# QSPI1 register map
Registers from a debugger description file.
Registers are 32-bit, access not given, no defined reset value unless marked. A register's access mark holds for its fields unless they carry their own. Addresses are absolute; registers are grouped by the start of their names; lines under a group give offsets from that group; [hi:lo] are bit positions; {n}, {i} and the like mark numbered series; 'fields as' and 'values as' point back to an identical list; <NAME> marks a mode.

## QSPI1
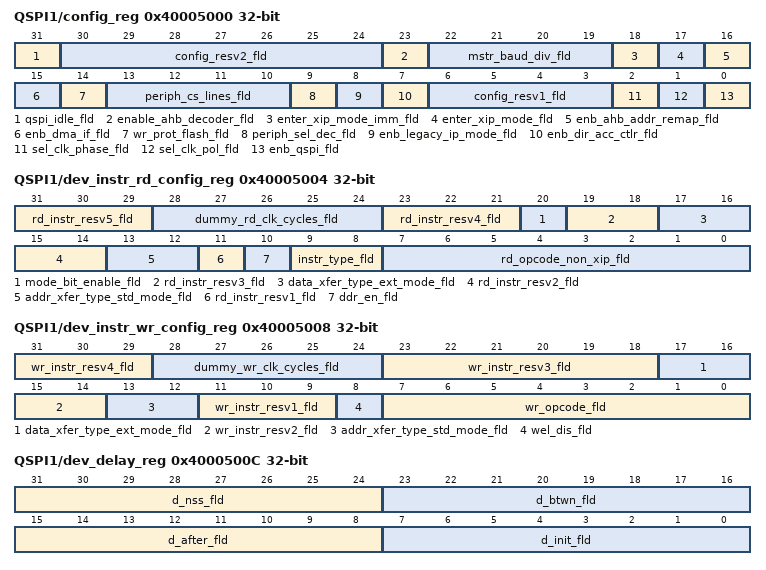
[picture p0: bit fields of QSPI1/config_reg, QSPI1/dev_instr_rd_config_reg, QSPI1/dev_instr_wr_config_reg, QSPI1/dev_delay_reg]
0x40005000 QSPI1/config_reg
  [31] qspi_idle_fld, [30:24] config_resv2_fld, [23] enable_ahb_decoder_fld, [22:19] mstr_baud_div_fld, [18] enter_xip_mode_imm_fld, [17] enter_xip_mode_fld, [16] enb_ahb_addr_remap_fld, [15] enb_dma_if_fld, [14] wr_prot_flash_fld, [13:10] periph_cs_lines_fld, [9] periph_sel_dec_fld, [8] enb_legacy_ip_mode_fld, [7] enb_dir_acc_ctlr_fld, [6:3] config_resv1_fld, [2] sel_clk_phase_fld, [1] sel_clk_pol_fld, [0] enb_qspi_fld
0x40005004 QSPI1/dev_instr_rd_config_reg
  [31:29] rd_instr_resv5_fld, [28:24] dummy_rd_clk_cycles_fld, [23:21] rd_instr_resv4_fld, [20] mode_bit_enable_fld, [19:18] rd_instr_resv3_fld, [17:16] data_xfer_type_ext_mode_fld, [15:14] rd_instr_resv2_fld, [13:12] addr_xfer_type_std_mode_fld, [11] rd_instr_resv1_fld, [10] ddr_en_fld, [9:8] instr_type_fld, [7:0] rd_opcode_non_xip_fld
0x40005008 QSPI1/dev_instr_wr_config_reg
  [31:29] wr_instr_resv4_fld, [28:24] dummy_wr_clk_cycles_fld, [23:18] wr_instr_resv3_fld, [17:16] data_xfer_type_ext_mode_fld, [15:14] wr_instr_resv2_fld, [13:12] addr_xfer_type_std_mode_fld, [11:9] wr_instr_resv1_fld, [8] wel_dis_fld, [7:0] wr_opcode_fld
0x4000500C QSPI1/dev_delay_reg
  [31:24] d_nss_fld, [23:16] d_btwn_fld, [15:8] d_after_fld, [7:0] d_init_fld
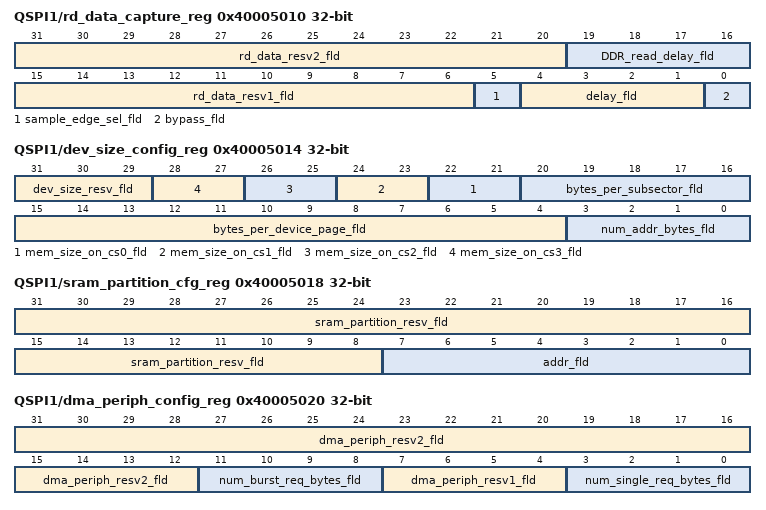
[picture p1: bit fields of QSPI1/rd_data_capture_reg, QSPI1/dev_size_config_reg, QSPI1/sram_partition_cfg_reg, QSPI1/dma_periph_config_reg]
0x40005010 QSPI1/rd_data_capture_reg
  [31:20] rd_data_resv2_fld, [19:16] DDR_read_delay_fld, [15:6] rd_data_resv1_fld, [5] sample_edge_sel_fld, [4:1] delay_fld, [0] bypass_fld
0x40005014 QSPI1/dev_size_config_reg
  [31:29] dev_size_resv_fld, [2n+22:2n+21] mem_size_on_cs{n}_fld (n=0..3), [20:16] bytes_per_subsector_fld, [15:4] bytes_per_device_page_fld, [3:0] num_addr_bytes_fld
0x40005018 QSPI1/sram_partition_cfg_reg
  [31:8] sram_partition_resv_fld, [7:0] addr_fld
0x4000501C QSPI1/ind_AHB_addr_trigger_reg
  [31:0] addr_fld
0x40005020 QSPI1/dma_periph_config_reg
  [31:12] dma_periph_resv2_fld, [11:8] num_burst_req_bytes_fld, [7:4] dma_periph_resv1_fld, [3:0] num_single_req_bytes_fld
0x40005024 QSPI1/remap_addr_reg
  [31:0] value_fld
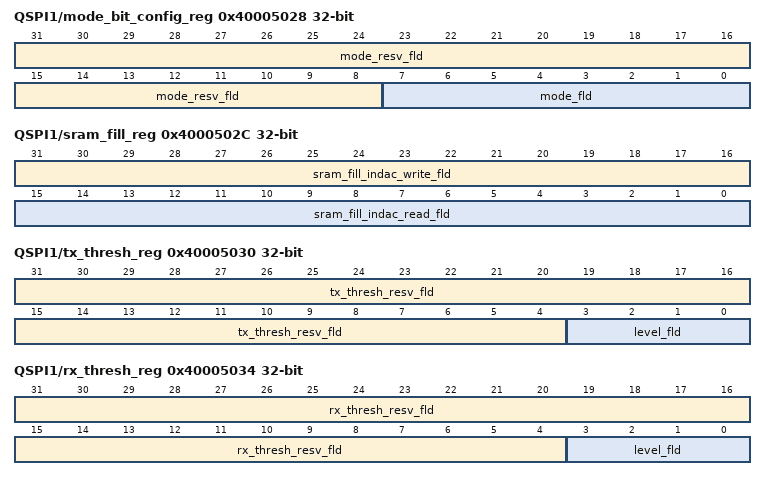
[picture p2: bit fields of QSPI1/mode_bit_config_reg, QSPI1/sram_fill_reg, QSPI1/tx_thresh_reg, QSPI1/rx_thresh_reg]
0x40005028 QSPI1/mode_bit_config_reg
  [31:8] mode_resv_fld, [7:0] mode_fld
0x4000502C QSPI1/sram_fill_reg
  [31:16] sram_fill_indac_write_fld, [15:0] sram_fill_indac_read_fld
0x40005030 QSPI1/tx_thresh_reg
  [31:4] tx_thresh_resv_fld, [3:0] level_fld
0x40005034 QSPI1/rx_thresh_reg
  [31:4] rx_thresh_resv_fld, [3:0] level_fld
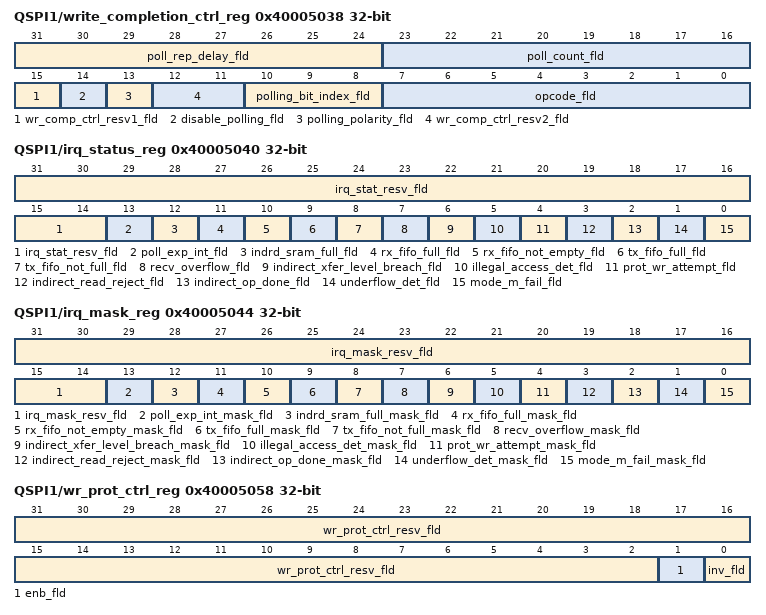
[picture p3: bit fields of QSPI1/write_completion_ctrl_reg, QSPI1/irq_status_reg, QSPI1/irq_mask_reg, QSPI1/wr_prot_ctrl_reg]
0x40005038 QSPI1/write_completion_ctrl_reg
  [31:24] poll_rep_delay_fld, [23:16] poll_count_fld, [15] wr_comp_ctrl_resv1_fld, [14] disable_polling_fld, [13] polling_polarity_fld, [12:11] wr_comp_ctrl_resv2_fld, [10:8] polling_bit_index_fld, [7:0] opcode_fld
0x4000503C QSPI1/no_of_polls_bef_exp_reg
  [31:0] no_of_polls_bef_exp_fld
0x40005040 QSPI1/irq_status_reg
  [31:14] irq_stat_resv_fld, [13] poll_exp_int_fld, [12] indrd_sram_full_fld, [11] rx_fifo_full_fld, [10] rx_fifo_not_empty_fld, [9] tx_fifo_full_fld, [8] tx_fifo_not_full_fld, [7] recv_overflow_fld, [6] indirect_xfer_level_breach_fld, [5] illegal_access_det_fld, [4] prot_wr_attempt_fld, [3] indirect_read_reject_fld, [2] indirect_op_done_fld, [1] underflow_det_fld, [0] mode_m_fail_fld
0x40005044 QSPI1/irq_mask_reg
  [31:14] irq_mask_resv_fld, [13] poll_exp_int_mask_fld, [12] indrd_sram_full_mask_fld, [11] rx_fifo_full_mask_fld, [10] rx_fifo_not_empty_mask_fld, [9] tx_fifo_full_mask_fld, [8] tx_fifo_not_full_mask_fld, [7] recv_overflow_mask_fld, [6] indirect_xfer_level_breach_mask_fld, [5] illegal_access_det_mask_fld, [4] prot_wr_attempt_mask_fld, [3] indirect_read_reject_mask_fld, [2] indirect_op_done_mask_fld, [1] underflow_det_mask_fld, [0] mode_m_fail_mask_fld
0x40005050 QSPI1/lower_wr_prot_reg
  [31:0] subsector_fld
0x40005054 QSPI1/upper_wr_prot_reg
  [31:0] subsector_fld
0x40005058 QSPI1/wr_prot_ctrl_reg
  [31:2] wr_prot_ctrl_resv_fld, [1] enb_fld, [0] inv_fld
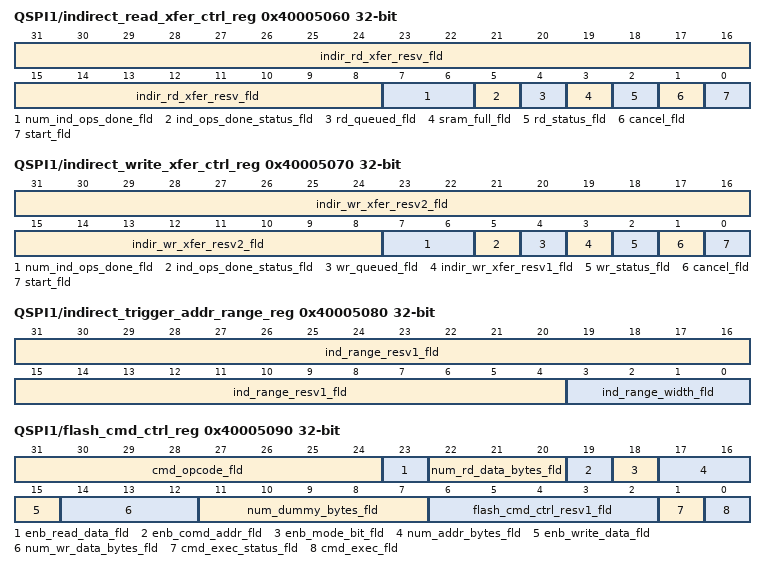
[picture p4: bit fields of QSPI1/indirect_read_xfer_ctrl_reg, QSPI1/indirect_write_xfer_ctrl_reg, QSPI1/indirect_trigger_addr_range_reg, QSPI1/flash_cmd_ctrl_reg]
0x40005060 QSPI1/indirect_read_xfer_ctrl_reg
  [31:8] indir_rd_xfer_resv_fld, [7:6] num_ind_ops_done_fld, [5] ind_ops_done_status_fld, [4] rd_queued_fld, [3] sram_full_fld, [2] rd_status_fld, [1] cancel_fld, [0] start_fld
0x40005064 QSPI1/indirect_read_xfer_watermark_reg
  [31:0] level_fld
0x40005068 QSPI1/indirect_read_xfer_start_reg
  [31:0] addr_fld
0x4000506C QSPI1/indirect_read_xfer_num_bytes_reg
  [31:0] value_fld
0x40005070 QSPI1/indirect_write_xfer_ctrl_reg
  [31:8] indir_wr_xfer_resv2_fld, [7:6] num_ind_ops_done_fld, [5] ind_ops_done_status_fld, [4] wr_queued_fld, [3] indir_wr_xfer_resv1_fld, [2] wr_status_fld, [1] cancel_fld, [0] start_fld
0x40005074 QSPI1/indirect_write_xfer_watermark_reg
  [31:0] level_fld
0x40005078 QSPI1/indirect_write_xfer_start_reg
  [31:0] addr_fld
0x4000507C QSPI1/indirect_write_xfer_num_bytes_reg
  [31:0] value_fld
0x40005080 QSPI1/indirect_trigger_addr_range_reg
  [31:4] ind_range_resv1_fld, [3:0] ind_range_width_fld
0x40005090 QSPI1/flash_cmd_ctrl_reg
  [31:24] cmd_opcode_fld, [23] enb_read_data_fld, [22:20] num_rd_data_bytes_fld, [19] enb_comd_addr_fld, [18] enb_mode_bit_fld, [17:16] num_addr_bytes_fld, [15] enb_write_data_fld, [14:12] num_wr_data_bytes_fld, [11:7] num_dummy_bytes_fld, [6:2] flash_cmd_ctrl_resv1_fld, [1] cmd_exec_status_fld, [0] cmd_exec_fld
0x40005094 QSPI1/flash_cmd_addr_reg
  [31:0] addr_fld
0x400050A0 QSPI1/flash_rd_data_lower_reg
  [31:0] data_fld
0x400050A4 QSPI1/flash_rd_data_upper_reg
  [31:0] data_fld
0x400050A8 QSPI1/flash_wr_data_lower_reg
  [31:0] data_fld
0x400050AC QSPI1/flash_wr_data_upper_reg
  [31:0] data_fld
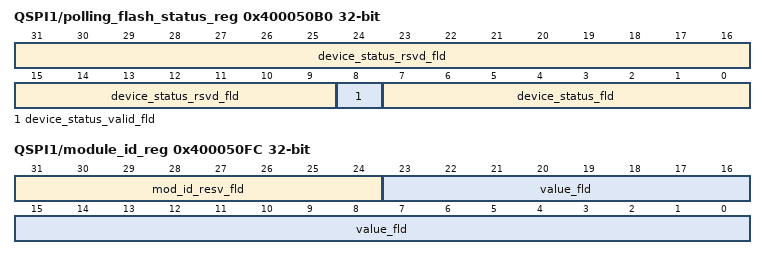
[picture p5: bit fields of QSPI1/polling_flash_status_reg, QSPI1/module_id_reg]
0x400050B0 QSPI1/polling_flash_status_reg
  [31:9] device_status_rsvd_fld, [8] device_status_valid_fld, [7:0] device_status_fld
0x400050FC QSPI1/module_id_reg
  [31:24] mod_id_resv_fld, [23:0] value_fld
